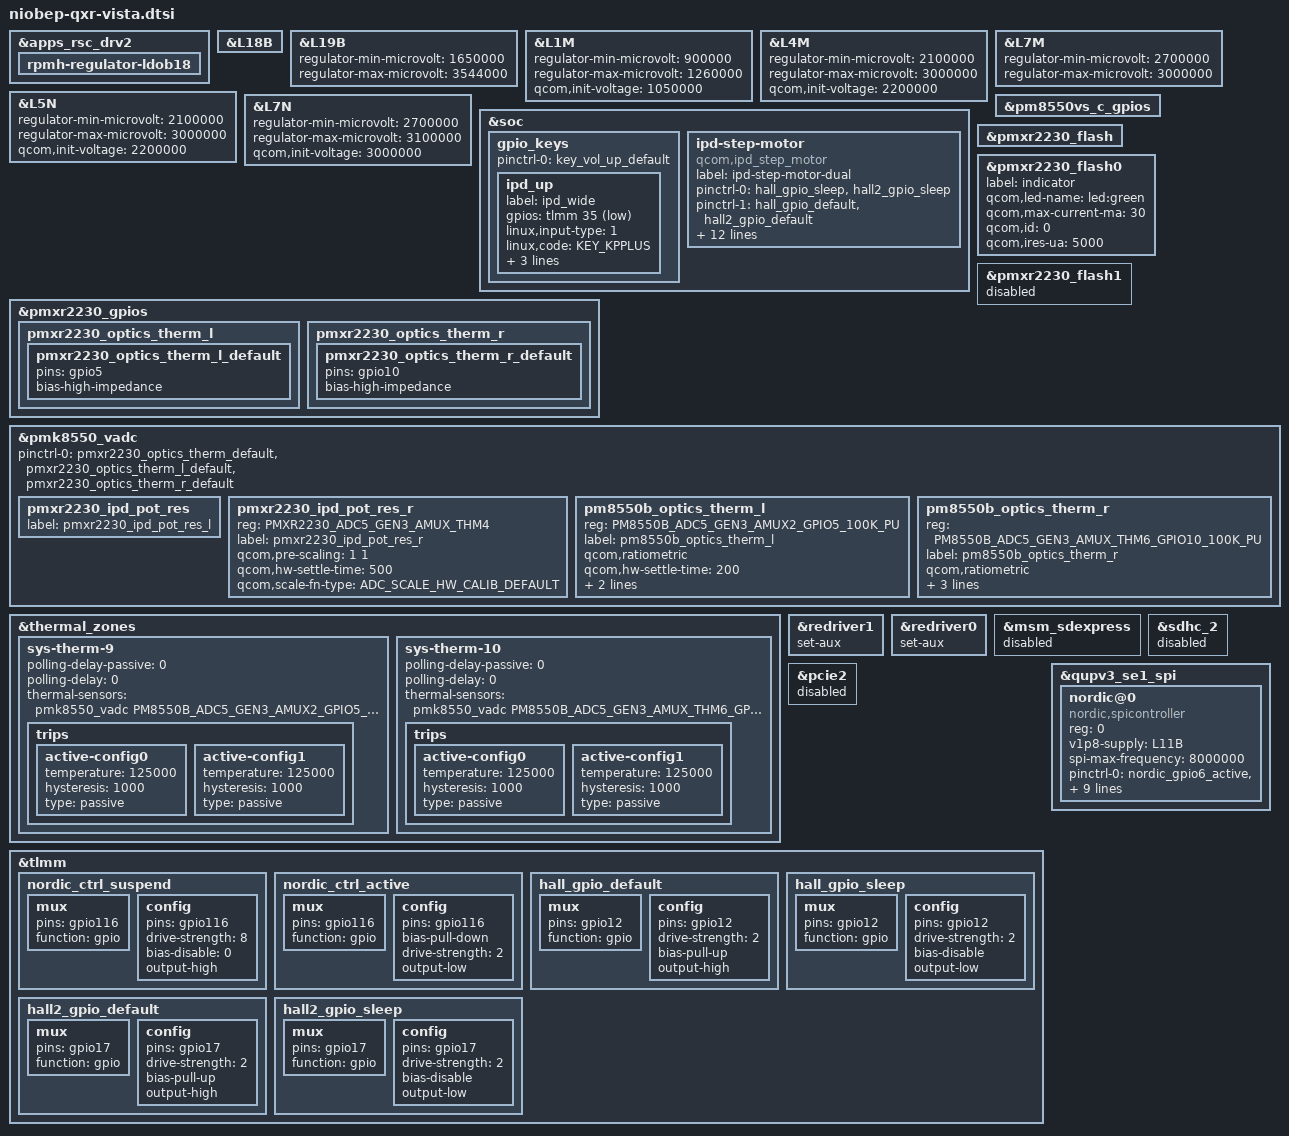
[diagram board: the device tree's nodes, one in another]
#include <dt-bindings/regulator/qcom,rpmh-regulator-levels.h>
#include "niobep-qxr.dtsi"

&apps_rsc_drv2 {
	rpmh-regulator-ldob18 {
		status = "ok";
	};
};

&L18B {
	status = "ok";
};

&L19B {
	regulator-min-microvolt = <1650000>;
	regulator-max-microvolt = <3544000>;
};

&L1M {
	regulator-min-microvolt = <900000>;
	regulator-max-microvolt = <1260000>;
	qcom,init-voltage = <1050000>;
};

&L4M {
	regulator-min-microvolt = <2100000>;
	regulator-max-microvolt = <3000000>;
	qcom,init-voltage = <2200000>;
};

&L7M {
	regulator-min-microvolt = <2700000>;
	regulator-max-microvolt = <3000000>;
};

&L5N {
	regulator-min-microvolt = <2100000>;
	regulator-max-microvolt = <3000000>;
	qcom,init-voltage = <2200000>;
};

&L7N {
	regulator-min-microvolt = <2700000>;
	regulator-max-microvolt = <3100000>;
	qcom,init-voltage = <3000000>;
};

&soc {
	gpio_keys {
		pinctrl-0 = <&key_vol_up_default>;

		/delete-node/ back_key;
		/delete-node/ confirm_key;
		/delete-node/ ipd_vol_up_default;
		/delete-node/ ipd_vol_down_default;
		/delete-node/ ipd_down;
		/delete-node/ ipd_up;

		ipd_up {
			label = "ipd_wide";
			gpios = <&tlmm 35 GPIO_ACTIVE_LOW>;
			linux,input-type = <1>;
			linux,code = <KEY_KPPLUS>;
			gpio-key,wakeup;
			debounce-interval = <15>;
			linux,can-disable;
		};
	};

	ipd-step-motor {
		status = "ok";
		compatible = "qcom,ipd_step_motor";
		label = "ipd-step-motor-dual";

		pinctrl-names = "sleep", "default";
		pinctrl-0 = <&hall_gpio_sleep &hall2_gpio_sleep>;
		pinctrl-1 = <&hall_gpio_default &hall2_gpio_default>;
		vdd-supply = <&L14B>;

		pwr-gpio = <&tlmm 11  0>;
		nsleep-gpio = <&tlmm 18  0>;

		step-gpio-left = <&tlmm 5  0>;
		nen-gpio-left = <&tlmm 62 0>;
		dir-gpio-left = <&tlmm  26 0>;

		step-gpio-right = <&tlmm 15  0>;
		nen-gpio-right = <&tlmm 29 0>;
		dir-gpio-right = <&tlmm  16 0>;

		io-channels = <&pmk8550_vadc PMXR2230_ADC5_GEN3_AMUX_THM5>,
				<&pmk8550_vadc PMXR2230_ADC5_GEN3_AMUX_THM4>;
		io-channel-names = "ipd_step_motor_left",
				"ipd_step_motor_right";
	};
};

&pm8550vs_c_gpios {
	/delete-node/ key_back_default;
	/delete-node/ key_confirm_default;
};

&pmxr2230_gpios {
	/delete-node/ flash_default;
};

&pmxr2230_flash {
	status = "ok";
	/delete-property/ qcom,external-led;
	/delete-property/ pinctrl-names;
	/delete-property/ pinctrl-0;
};

&pmxr2230_flash0 {
	label = "indicator";
	qcom,led-name = "led:green";
	qcom,max-current-ma = <30>;
	qcom,id = <0>;
	qcom,ires-ua = <5000>;

	/delete-property/ qcom,strobe-sel;
	/delete-property/ qcom,strobe-config;
	/delete-property/ qcom,default-led-trigger;
	/delete-property/ qcom,duration-ms;
};

&pmxr2230_flash1 {
	status = "disabled";
};

&pmxr2230_gpios {
	pmxr2230_optics_therm_l {
		pmxr2230_optics_therm_l_default: pmxr2230_optics_therm_l_default {
			pins = "gpio5";
			bias-high-impedance;
		};
	};

	pmxr2230_optics_therm_r {
		pmxr2230_optics_therm_r_default: pmxr2230_optics_therm_r_default {
			pins = "gpio10";
			bias-high-impedance;
		};
	};
};

&pmk8550_vadc {
	pinctrl-0 = <&pmxr2230_optics_therm_default
		     &pmxr2230_optics_therm_l_default
		     &pmxr2230_optics_therm_r_default>;

	/delete-node/ pmxr2230_sde_card_therm;

	pmxr2230_ipd_pot_res {
		label = "pmxr2230_ipd_pot_res_l";
	};

	pmxr2230_ipd_pot_res_r {
		reg = <PMXR2230_ADC5_GEN3_AMUX_THM4>;
		label = "pmxr2230_ipd_pot_res_r";
		qcom,pre-scaling = <1 1>;
		qcom,hw-settle-time = <500>;
		qcom,scale-fn-type = <ADC_SCALE_HW_CALIB_DEFAULT>;
	};

	pm8550b_optics_therm_l {
		reg = <PM8550B_ADC5_GEN3_AMUX2_GPIO5_100K_PU>;
		label = "pm8550b_optics_therm_l";
		qcom,ratiometric;
		qcom,hw-settle-time = <200>;
		qcom,pre-scaling = <1 1>;
		qcom,adc-tm-type = <1>;
	};

	pm8550b_optics_therm_r {
		reg = <PM8550B_ADC5_GEN3_AMUX_THM6_GPIO10_100K_PU>;
		label = "pm8550b_optics_therm_r";
		qcom,ratiometric;
		qcom,hw-settle-time = <200>;
		qcom,pre-scaling = <1 1>;
		qcom,adc-tm-type = <1>;
	};
};

&thermal_zones {
	/delete-node/ sys-therm-5;

	sys-therm-9 {
		polling-delay-passive = <0>;
		polling-delay = <0>;
		thermal-sensors = <&pmk8550_vadc PM8550B_ADC5_GEN3_AMUX2_GPIO5_100K_PU>;
		trips {
			active-config0 {
				temperature = <125000>;
				hysteresis = <1000>;
				type = "passive";
			};

			active-config1 {
				temperature = <125000>;
				hysteresis = <1000>;
				type = "passive";
			};
		};
	};

	sys-therm-10 {
		polling-delay-passive = <0>;
		polling-delay = <0>;
		thermal-sensors = <&pmk8550_vadc PM8550B_ADC5_GEN3_AMUX_THM6_GPIO10_100K_PU>;
		trips {
			active-config0 {
				temperature = <125000>;
				hysteresis = <1000>;
				type = "passive";
			};

			active-config1 {
				temperature = <125000>;
				hysteresis = <1000>;
				type = "passive";
			};
		};
	};
};

&redriver1 {
	set-aux;
};

&redriver0 {
	set-aux;
};

&msm_sdexpress {
	status = "disabled";
};

&sdhc_2 {
	status = "disabled";
};

&pcie2 {
	status = "disabled";
};

/delete-node/ &nordic_ctrl_suspend;
/delete-node/ &nordic_ctrl_active;

&tlmm {
	nordic_ctrl_suspend: nordic_ctrl_suspend {
		mux {
			pins = "gpio116";
			function = "gpio";
		};

		config {
			pins = "gpio116";
			drive-strength = <8>;
			bias-disable = <0>;
			output-high;
		};
	};

	/* active low due to hmd nordic */
	nordic_ctrl_active: nordic_ctrl_active {
		mux {
			pins = "gpio116";
			function = "gpio";
		};

		config {
			pins = "gpio116";
			bias-pull-down; /* PULL DOWN */
			drive-strength = <2>; /* 2 MA */
			output-low;
		};
	};

	hall_gpio_default: hall_gpio_default {
		mux {
			pins = "gpio12";
			function = "gpio";
		};

		config {
			pins = "gpio12";
			drive-strength = <2>;
			bias-pull-up;
			output-high;
		};
	};

	hall_gpio_sleep: hall_gpio_sleep {
		mux {
			pins = "gpio12";
			function = "gpio";
		};

		config {
			pins = "gpio12";
			drive-strength = <2>;
			bias-disable;
			output-low;
		};
	};

	hall2_gpio_default: hall2_gpio_default {
		mux {
			pins = "gpio17";
			function = "gpio";
		};

		config {
			pins = "gpio17";
			drive-strength = <2>;
			bias-pull-up;
			output-high;
		};
	};

	hall2_gpio_sleep: hall2_gpio_sleep {
		mux {
			pins = "gpio17";
			function = "gpio";
		};

		config {
			pins = "gpio17";
			drive-strength = <2>;
			bias-disable;
			output-low;
		};
	};
};

&qupv3_se1_spi {
	status = "okay";

	nordic@0 {
		compatible = "nordic,spicontroller";
		reg = <0>;

		v1p8-supply = <&L11B>;
		spi-max-frequency = <8000000>;
		pinctrl-names = "nordic_default", "nordic_sleep";
		pinctrl-0 = <&nordic_gpio6_active &nordic_ctrl_active>;
		pinctrl-1 = <&nordic_gpio6_suspend &nordic_ctrl_suspend>;

		nordic,ledl-gpio = <&tlmm 116 0>;
		nordic,ledr-gpio = <&tlmm 4 0>;

		interrupt-parent = <&tlmm>;
		interrupt-names = "nordicspi_irq";
		nordic,irq-gpio = <&tlmm 52 0>;
		nordic,irq_pin = <&tlmm 52 0x00>;
		interrupts = <52 1>;
	};
};
